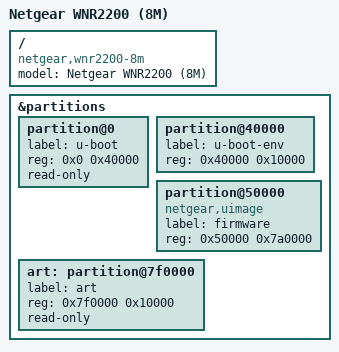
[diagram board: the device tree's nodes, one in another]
// SPDX-License-Identifier: GPL-2.0-or-later OR MIT
/dts-v1/;

#include "ar7241_netgear_wnr2200.dtsi"

/ {
	compatible = "netgear,wnr2200-8m", "qca,ar7241";
	model = "Netgear WNR2200 (8M)";
};

&partitions {
	partition@0 {
		label = "u-boot";
		reg = <0x0 0x40000>;
		read-only;
	};

	partition@40000 {
		label = "u-boot-env";
		reg = <0x40000 0x10000>;
	};

	partition@50000 {
		label = "firmware";
		reg = <0x50000 0x7a0000>;
		compatible = "netgear,uimage";
	};

	art: partition@7f0000 {
		label = "art";
		reg = <0x7f0000 0x10000>;
		read-only;
	};
};
